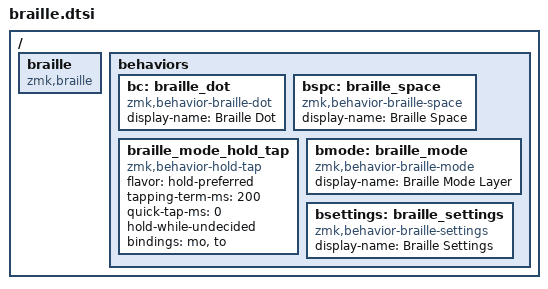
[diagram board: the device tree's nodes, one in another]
/* SPDX-License-Identifier: MIT */

#ifndef ZMK_BRAILLE_BEHAVIORS_DTSI
#define ZMK_BRAILLE_BEHAVIORS_DTSI

#include <behaviors/momentary_layer.dtsi>
#include <behaviors/to_layer.dtsi>

/ {
    braille: braille {
        compatible = "zmk,braille";
    };

    behaviors {
        bc: braille_dot {
            compatible = "zmk,behavior-braille-dot";
            #binding-cells = <1>;
            display-name = "Braille Dot";
        };

        bspc: braille_space {
            compatible = "zmk,behavior-braille-space";
            #binding-cells = <0>;
            display-name = "Braille Space";
        };

        /* One-parameter bmode adapts its target to both hold/tap parameters. */
        braille_mode_hold_tap: braille_mode_hold_tap {
            compatible = "zmk,behavior-hold-tap";
            #binding-cells = <2>;
            flavor = "hold-preferred";
            tapping-term-ms = <200>;
            quick-tap-ms = <0>;
            hold-while-undecided;
            bindings = <&mo>, <&to>;
        };

        bmode: braille_mode {
            compatible = "zmk,behavior-braille-mode";
            #binding-cells = <1>;
            display-name = "Braille Mode Layer";
        };

        bsettings: braille_settings {
            compatible = "zmk,behavior-braille-settings";
            #binding-cells = <0>;
            display-name = "Braille Settings";
        };
    };
};

#endif /* ZMK_BRAILLE_BEHAVIORS_DTSI */
